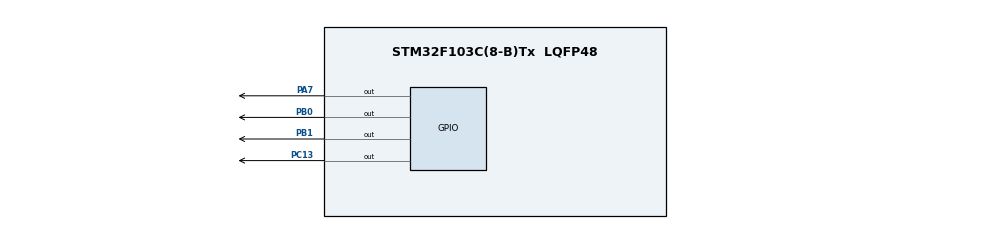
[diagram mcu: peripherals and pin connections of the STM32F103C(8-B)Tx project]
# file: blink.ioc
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Mcu.Family=STM32F1
PC13-TAMPER-RTC.Signal=GPIO_Output
ProjectManager.StackSize=0x400
PB0.GPIO_Speed=GPIO_SPEED_FREQ_MEDIUM
PA13.Signal=SYS_JTMS-SWDIO
ProjectManager.TargetToolchain=MDK-ARM V5.27
PA7.PinState=GPIO_PIN_SET
PB0.PinState=GPIO_PIN_SET
board=custom
PA7.GPIO_Speed=GPIO_SPEED_FREQ_MEDIUM
RCC.APB2Freq_Value=8000000
PC13-TAMPER-RTC.PinState=GPIO_PIN_SET
PB1.GPIO_Speed=GPIO_SPEED_FREQ_MEDIUM
PA14.Mode=Serial_Wire
PA13.Mode=Serial_Wire
Mcu.Name=STM32F103C(8-B)Tx
PB1.PinState=GPIO_PIN_SET
Mcu.Package=LQFP48
PB1.Signal=GPIO_Output
PA14.Signal=SYS_JTCK-SWCLK
ProjectManager.HeapSize=0x200
NVIC.PriorityGroup=NVIC_PRIORITYGROUP_4
RCC.APB1Freq_Value=8000000
PB0.Signal=GPIO_Output
PA7.Signal=GPIO_Output

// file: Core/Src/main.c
/* USER CODE BEGIN Header */
/**
  ******************************************************************************
  * @file           : main.c
  * @brief          : Main program body
  ******************************************************************************
  * @attention
  *
  * <h2><center>&copy; Copyright (c) 2020 STMicroelectronics.
  * All rights reserved.</center></h2>
  *
  * This software component is licensed by ST under BSD 3-Clause license,
  * the "License"; You may not use this file except in compliance with the
  * License. You may obtain a copy of the License at:
  *                        opensource.org/licenses/BSD-3-Clause
  *
  ******************************************************************************
  */
/* USER CODE END Header */
#include "main.h"
#include "Types.h"
#include "Lcd.h"
#include "ShiftReg.h"

void SystemClock_Config(void);
static void MX_GPIO_Init(void);

int main(void)
{
  /* USER CODE BEGIN 1 */
  unsigned char message[] = "message";
  /* USER CODE END 1 */

  /* MCU Configuration--------------------------------------------------------*/

  /* Reset of all peripherals, Initializes the Flash interface and the Systick. */
  HAL_Init();

  /* Configure the system clock */
  SystemClock_Config();

  /* Initialize all configured peripherals */
  MX_GPIO_Init();
  LCD_Init();
  (void) LCD_GotoXY(2, 1);
  if (sizeof(unsigned short int) == 2)
  LCD_PutString((uint8 *)message);
  /* Infinite loop */
  while (1)
  {
  }
}

void SystemClock_Config(void)
{
  RCC_OscInitTypeDef RCC_OscInitStruct = {0};
  RCC_ClkInitTypeDef RCC_ClkInitStruct = {0};

  /** Initializes the RCC Oscillators according to the specified parameters
  * in the RCC_OscInitTypeDef structure.
  */
  RCC_OscInitStruct.OscillatorType = RCC_OSCILLATORTYPE_HSI;
  RCC_OscInitStruct.HSIState = RCC_HSI_ON;
  RCC_OscInitStruct.HSICalibrationValue = RCC_HSICALIBRATION_DEFAULT;
  RCC_OscInitStruct.PLL.PLLState = RCC_PLL_NONE;
  if (HAL_RCC_OscConfig(&RCC_OscInitStruct) != HAL_OK)
  {
    Error_Handler();
  }
  /** Initializes the CPU, AHB and APB buses clocks
  */
  RCC_ClkInitStruct.ClockType = (RCC_CLOCKTYPE_HCLK|RCC_CLOCKTYPE_SYSCLK | \
                                  RCC_CLOCKTYPE_PCLK1|RCC_CLOCKTYPE_PCLK2);
  RCC_ClkInitStruct.SYSCLKSource = RCC_SYSCLKSOURCE_HSI;
  RCC_ClkInitStruct.AHBCLKDivider = RCC_SYSCLK_DIV1;
  RCC_ClkInitStruct.APB1CLKDivider = RCC_HCLK_DIV1;
  RCC_ClkInitStruct.APB2CLKDivider = RCC_HCLK_DIV1;

  if (HAL_RCC_ClockConfig(&RCC_ClkInitStruct, FLASH_LATENCY_0) != HAL_OK)
  {
    Error_Handler();
  }
}

static void MX_GPIO_Init(void)
{
  GPIO_InitTypeDef GPIO_InitStruct = {0};

  /* GPIO Ports Clock Enable */
  __HAL_RCC_GPIOC_CLK_ENABLE();
  __HAL_RCC_GPIOA_CLK_ENABLE();
  __HAL_RCC_GPIOB_CLK_ENABLE();

  /*Configure GPIO pin Output Level */
  HAL_GPIO_WritePin(GPIOC, GPIO_PIN_13, GPIO_PIN_SET);

  /*Configure GPIO pin Output Level */
  HAL_GPIO_WritePin(GPIOA, GPIO_PIN_7, GPIO_PIN_SET);

  /*Configure GPIO pin Output Level */
  HAL_GPIO_WritePin(GPIOB, GPIO_PIN_0|GPIO_PIN_1, GPIO_PIN_SET);

  /*Configure GPIO pin : PC13 */
  GPIO_InitStruct.Pin = GPIO_PIN_13;
  GPIO_InitStruct.Mode = GPIO_MODE_OUTPUT_PP;
  GPIO_InitStruct.Pull = GPIO_NOPULL;
  GPIO_InitStruct.Speed = GPIO_SPEED_FREQ_LOW;
  HAL_GPIO_Init(GPIOC, &GPIO_InitStruct);

  /*Configure GPIO pin : PA7 */
  GPIO_InitStruct.Pin = GPIO_PIN_7;
  GPIO_InitStruct.Mode = GPIO_MODE_OUTPUT_PP;
  GPIO_InitStruct.Pull = GPIO_NOPULL;
  GPIO_InitStruct.Speed = GPIO_SPEED_FREQ_MEDIUM;
  HAL_GPIO_Init(GPIOA, &GPIO_InitStruct);

  /*Configure GPIO pins : PB0 PB1 */
  GPIO_InitStruct.Pin = GPIO_PIN_0|GPIO_PIN_1;
  GPIO_InitStruct.Mode = GPIO_MODE_OUTPUT_PP;
  GPIO_InitStruct.Pull = GPIO_NOPULL;
  GPIO_InitStruct.Speed = GPIO_SPEED_FREQ_MEDIUM;
  HAL_GPIO_Init(GPIOB, &GPIO_InitStruct);

}

void Error_Handler(void)
{
  __disable_irq();
  while (1)
  {
  }
}

/************************ (C) COPYRIGHT STMicroelectronics *****END OF FILE****/
